# AM335x register map
Vendor: Texas Instruments; Series: Sitara AM335x; File version: 1.1
CPU: Cortex-A8 r0p0, little endian
Registers are 32-bit, read-write, reset 0x0 unless marked. A register's access mark holds for its fields unless they carry their own. Offsets are from the block's base; [hi:lo] are bit positions; {n}, {i} and the like mark numbered series; 'fields as' and 'values as' point back to an identical list.

## EDMATC0 — EDMA transfer controller module 0
Base 0x49800000
Same registers: EDMATC1 0x49900000, EDMATC2 0x49A00000
0x00 PID — PIDTC Register
  [15:0] PID — bits 0..15 (R) Peripheral identifier uniquely identifies the EDMA3CC and the
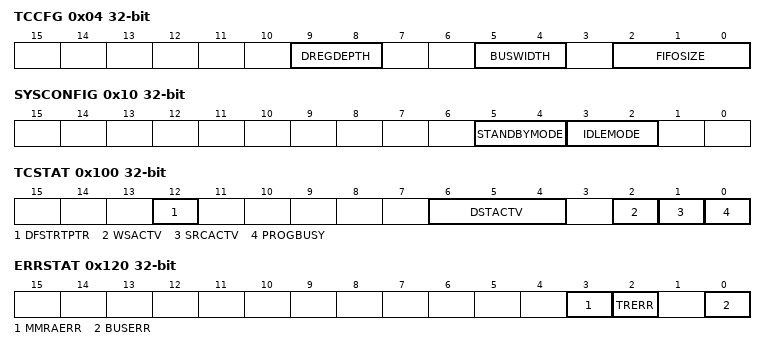
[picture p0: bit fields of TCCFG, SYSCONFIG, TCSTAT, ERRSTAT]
0x04 TCCFG
  [9:8] DREGDEPTH — bits 8,9 (R) Register file depth
  [5:4] BUSWIDTH — bits 4,5 (R) Bus width configuration
  [2:0] FIFOSIZE — bits 0..2 (R) FIFO size configuration
0x10 SYSCONFIG — SYSCONFIGTC Register
  [5:4] STANDBYMODE — bits 4,5 (RW) Standby mode configuration [see e_SYSC_STANDBYMODE]
  [3:2] IDLEMODE — bits 2,3 (RW) Idle mode configuration [see e_SYSC_IDLEMODE]
0x100 TCSTAT
  [12] DFSTRTPTR — bits 12,13 (R) Destination FIFO start pointer.
  [6:4] DSTACTV — bits 4..6 (R) Destination active state. [ see e_DSTACTV_state ]
  [2] WSACTV — bit 2 (R) Write status active
  [1] SRCACTV — bit 1 (R) Source active state
  [0] PROGBUSY — bit 0 (R) Program register set busy
0x120 ERRSTAT
  [3] MMRAERR — bit 3 (R) MMR address error.
  [2] TRERR — bit 2 (R) Transfer request (TR) error event.
  [0] BUSERR — bit 0 (R) Bus error event.
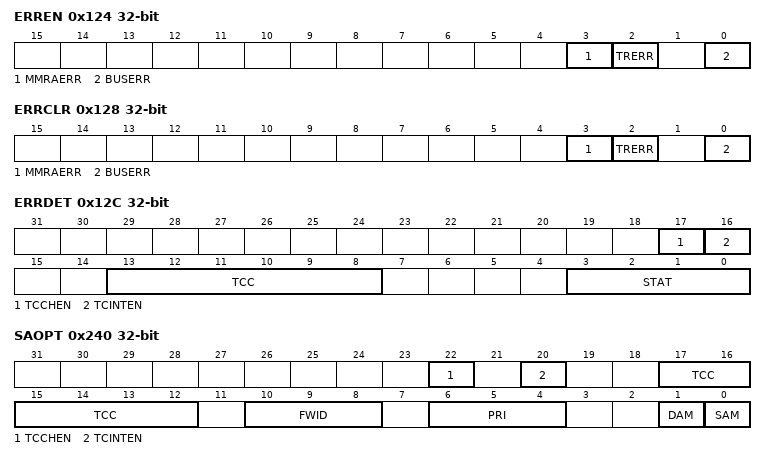
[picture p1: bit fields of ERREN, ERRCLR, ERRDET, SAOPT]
0x124 ERREN
  [3] MMRAERR — bit 3 (RW) Interrupt enable for MMR address error (MMRAERR).
  [2] TRERR — bit 2 (RW) Interrupt enable for transfer request error (TRERR).
  [0] BUSERR — bit 0 (RW) Interrupt enable for bus error (BUSERR).
0x128 ERRCLR
  [3] MMRAERR — bit 3 (W) Interrupt enable clear for the MMRAERR bit in the error status
  [2] TRERR — bit 2 (W) Interrupt enable clear for the TRERR bit in the error status register
  [0] BUSERR — bit 0 (W) Interrupt clear for the BUSERR bit in the error status register
0x12C ERRDET
  [17] TCCHEN — bit 17 (R) Transfer completion chaining enable.
  [16] TCINTEN — bit 16 (R) Transfer completion interrupt enable.
  [13:8] TCC — bits 8..13 (R) Transfer complete code.
  [3:0] STAT — bits 0..3 (R) Transaction status.
0x130 ERRCMD
  [0] EVAL — bit 0 (W) Error evaluate
0x140 RDRATE
  [2:0] RDRATE — bits 0..2 (W) Read rate.
0x240 SAOPT
  [22] TCCHEN — bit 22 (R) Transfer complete chaining enable
  [20] TCINTEN — bit 20 (R) Transfer complete interrupt enable.
  [17:12] TCC — bits 12..17 (R) Transfer complete code.
  [10:8] FWID — bits 8..10 (R) FIFO width.
  [6:4] PRI — bits 4..6 (R) Transfer priority.
  [1] DAM — bit 1 (R) Destination address mode within an array
  [0] SAM — bit 0 (R) Source address mode within an array
0x244 SASRC
  [31:0] SADDR — bits 0..31 (R) Source address for Source Active Register Set.
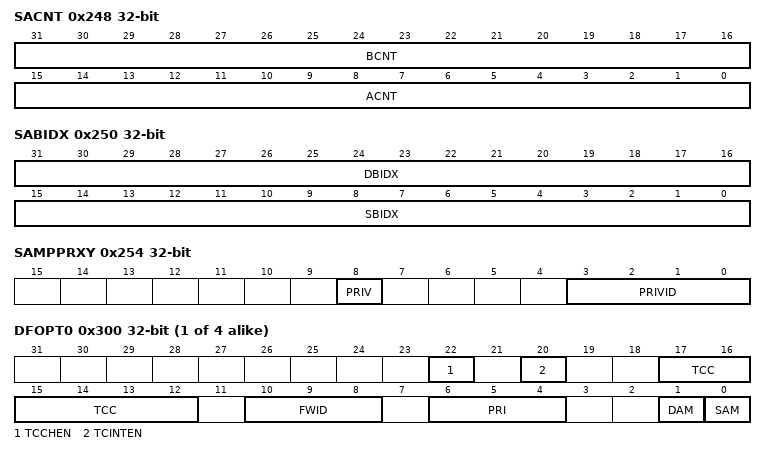
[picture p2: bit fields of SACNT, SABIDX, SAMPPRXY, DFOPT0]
0x248 SACNT
  [31:16] BCNT — bits 16..31 (R) B dimension count remaining for the Source Active Register Set.
  [15:0] ACNT — bits 0..15 (R) A dimension count remaining for the Source Active Register Set.
0x24C SADST
0x250 SABIDX
  [31:16] DBIDX — bits 16..31 (R) B-Index offset between destination arrays.
  [15:0] SBIDX — bits 0..15 (R) B-Index offset between source arrays.
0x254 SAMPPRXY
  [8] PRIV — bit 8 (R) Privilege level.
  [3:0] PRIVID — bits 0..3 (R) Privilege ID.
0x258 SACNTRLD
  [15:0] ACNTRLD — bits 0..15 (R) A-count reload value.
0x25C SASRCBREF
  [31:0] SADDRBREF — bits 0..31 (R) Source address B-reference.
0x260 SADSTBREF
0x280 DFCNTRLD
  [15:0] ACNTRLD — bits 0..15 (R) A-count reload value for the Destination FIFO Register Set.
0x284 DFSRCBREF
0x288 DFDSTBREF
  [31:0] DADDRBREF — bits 0..31 (R) Destination address reference for the destination FIFO register set.
{0x300+0x40*i} DFOPT{i} (i=0..3) — DFOPT Register
  [22] TCCHEN — bit 22 (R) Transfer complete chaining enable
  [20] TCINTEN — bit 20 (R) Transfer complete interrupt enable.
  [17:12] TCC — bits 12..17 (R) Transfer complete code.
  [10:8] FWID — bits 8..10 (R) FIFO width.
  [6:4] PRI — bits 4..6 (R) Transfer priority [ see e_PRI ]
  [1] DAM — bit 1 (R) Destination address mode within an array
  [0] SAM — bit 0 (R) Source address mode within an array
{0x304+0x40*i} DFSRC{i} (i=0..3) — DFSRC Register
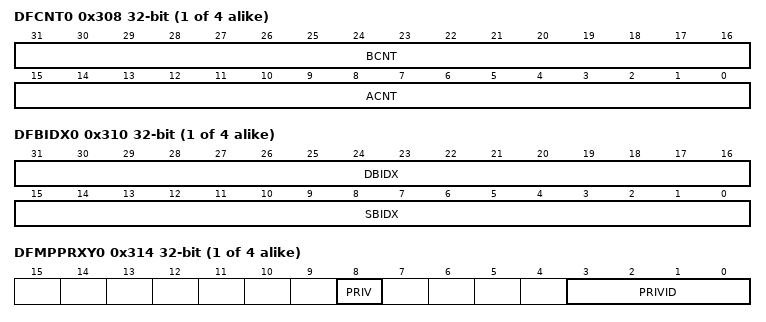
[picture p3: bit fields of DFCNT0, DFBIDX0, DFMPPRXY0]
{0x308+0x40*i} DFCNT{i} (i=0..3) — DFCNT Register
  [31:16] BCNT — bits 16..31 (R) B-dimension count remaining for Destination Register Set.
  [15:0] ACNT — bits 0..15 (R) A-dimension count remaining for Destination Register Set.
{0x30C+0x40*i} DFDST{i} (i=0..3) — DFDST Register
  [31:0] DADDR — bits 0..31 (R) Destination address for the destination FIFO register set.
{0x310+0x40*i} DFBIDX{i} (i=0..3) — DFBIDX Register
  [31:16] DBIDX — bits 16..31 (R) B-Index offset between destination arrays for the Destination FIFO
  [15:0] SBIDX — bits 0..15 (R) B-Index offset between source arrays for the Destination FIFO
{0x314+0x40*i} DFMPPRXY{i} (i=0..3) — DFMPPRXY Register
  fields as SAMPPRXY
